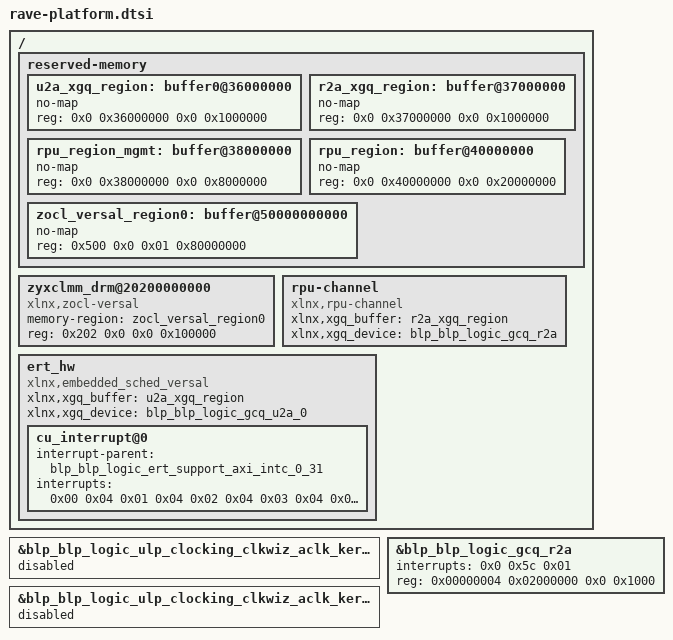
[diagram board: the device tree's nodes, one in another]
/ {
	reserved-memory {
        	#address-cells = <0x2>;
        	#size-cells = <0x2>;
        	ranges;

        	u2a_xgq_region: buffer0@36000000 {
            		no-map;
            		reg = <0x0 0x36000000 0x0 0x1000000>;
        	};

        	r2a_xgq_region: buffer@37000000 {
            		no-map;
            		reg = <0x0 0x37000000 0x0 0x1000000>;
        	};

		rpu_region_mgmt: buffer@38000000 {
                        no-map;
                        reg = <0x0 0x38000000 0x0 0x8000000>;
                };

		rpu_region: buffer@40000000 {
			no-map;
			reg = <0x0 0x40000000 0x0 0x20000000>;
		};

        	zocl_versal_region0: buffer@50000000000 {
            		no-map;
            		reg = <0x500 0x0 0x01 0x80000000>;
        	};

    	};
	zyxclmm_drm@20200000000 {
                compatible = "xlnx,zocl-versal";
                status = "okay";
                memory-region = <&zocl_versal_region0>;
                reg = <0x202 0x0 0x0 0x100000>;
        };
	rpu-channel {
                compatible = "xlnx,rpu-channel";
                xlnx,xgq_buffer = <&r2a_xgq_region>;
                xlnx,xgq_device = <&blp_blp_logic_gcq_r2a>;
                interrupt-names = "irq_sq";
        };
	ert_hw {
                compatible = "xlnx,embedded_sched_versal";
                status = "okay";
                xlnx,xgq_buffer = <&u2a_xgq_region>;
                xlnx,xgq_device = <&blp_blp_logic_gcq_u2a_0>;
                interrupt-names = "irq_sq";
                cu_interrupt@0 {
                        interrupt-parent = <&blp_blp_logic_ert_support_axi_intc_0_31>;
                        interrupts = <0x00 0x04 0x01 0x04 0x02 0x04 0x03 0x04 0x04 0x04 0x05 0x04 0x06 0x04 0x07 0x04 0x08 0x04 0x09 0x04 0x0a 0x04 0x0b 0x04 0x0c 0x04 0x0d 0x04 0x0e 0x04 0x0f 0x04 0x10 0x04 0x11 0x04 0x12 0x04 0x13 0x04 0x14 0x04 0x15 0x04 0x16 0x04 0x17 0x04 0x18 0x04 0x19 0x04 0x1a 0x04 0x1b 0x04 0x1c 0x04 0x1d 0x04 0x1e 0x04 0x1f 0x04>;
                };
       };
};

&blp_blp_logic_ulp_clocking_clkwiz_aclk_kernel_01 {
	status = "disabled";
};

&blp_blp_logic_ulp_clocking_clkwiz_aclk_kernel_00 {
	status = "disabled";
};

&blp_blp_logic_gcq_r2a {
        interrupts = <0x0 0x5c 0x01>;
        reg = <0x00000004 0x02000000 0x0 0x1000>;
};
